# RA register map
Vendor: Renesas; Series: All Chips; File version: x.xx
Registers are 32-bit, read-write, reset 0x0 unless marked. A register's access mark holds for its fields unless they carry their own. Offsets are from the block's base; [hi:lo] are bit positions; {n}, {i} and the like mark numbered series; 'fields as' and 'values as' point back to an identical list; <NAME> marks a mode.

## R_GPT0 — General PWM Timer
Base 0x40169000
Same registers: R_GPT10 0x40078A00, R_GPT11 0x40078B00, R_GPT12 0x40078C00, R_GPT13 0x40078D00, R_GPT{n} {0x40169000+0x100*n} (n=1..9)
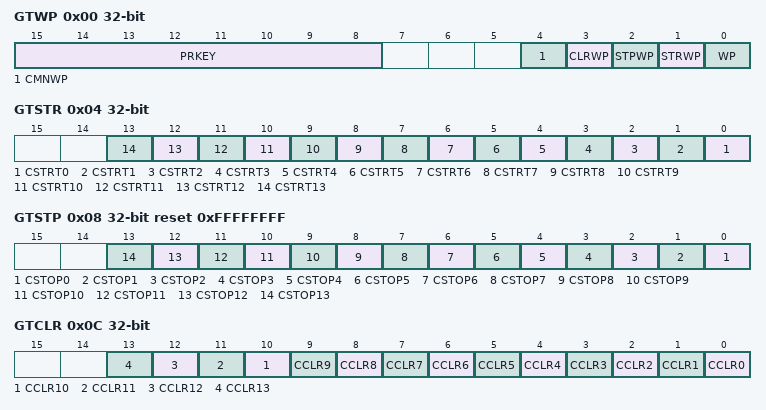
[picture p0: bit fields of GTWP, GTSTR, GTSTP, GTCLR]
0x00 GTWP — General PWM Timer Write-Protection Register
  [15:8] PRKEY wo — GTWP Key Code
    165=Written to these bits, the WP bits write is permitted; other=others (The WP bits write is not permitted.)
  [4] CMNWP — Common Register Write Disabled
    0=Write to the register is enabled; 1=Write to the register is disabled
  [3] CLRWP — GTCLR.CCLR Bit Write Disable
    0=Write to the bit is enabled; 1=Write to the bit is disabled
  [2] STPWP — GTSTP.CSTOP Bit Write Disable
    values as CLRWP
  [1] STRWP — GTSTR.CSTRT Bit Write Disable
    values as CLRWP
  [0] WP — Register Write Disable
    values as CMNWP
0x04 GTSTR — General PWM Timer Software Start Register
  [n] CSTRT{n} (n=0..13) — Channel GTCNT Count StartRead data shows each channel's counter status (GTCR.CST bit). 0 means counter stop. 1 means counter running.
    0=No effect (write) / counter stop (read); 1=GTCNT counter starts (write) / Counter running (read)
0x08 GTSTP reset 0xFFFFFFFF — General PWM Timer Software Stop Register
  [n] CSTOP{n} (n=0..13) — Channel GTCNT Count StopRead data shows each channel's counter status (GTCR.CST bit). 0 means counter runnning. 1 means counter stop.
    0=No effect (write) / counter running (read); 1=GPT GTCNT counter stops (write) / Counter stop (read)
0x0C GTCLR wo — General PWM Timer Software Clear Register
  [n] CCLR{n} (n=0..13) — Channel GTCNT Count Clear
    0=No effect; 1=GPT GTCNT counter clears
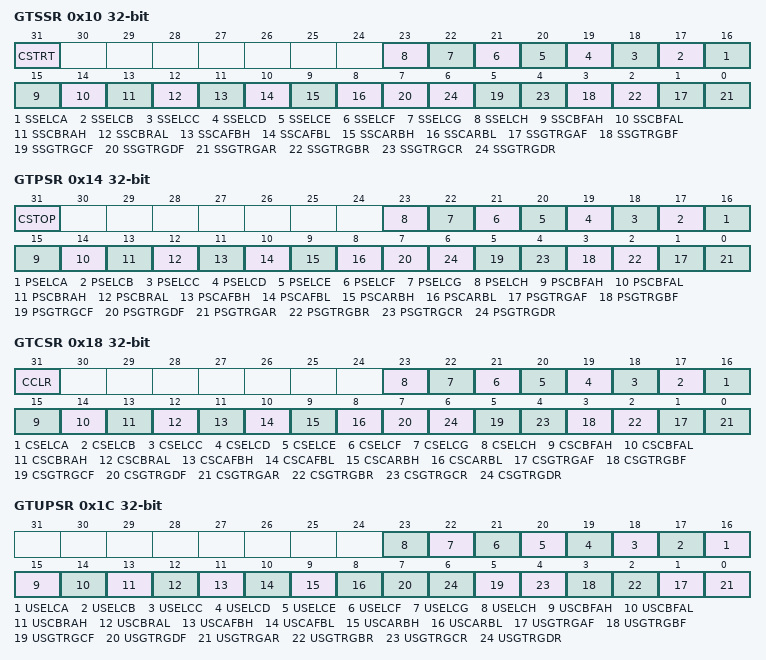
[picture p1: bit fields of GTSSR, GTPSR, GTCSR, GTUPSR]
0x10 GTSSR — General PWM Timer Start Source Select Register
  [31] CSTRT — Software Source Counter Start Enable
    0=Counter start is disable by the GTSTR register; 1=Counter start is enable by the GTSTR register
  [16] SSELC{x} (x=A,B,C,D,E,F,G,H; step 1) — ELC_GPT Event Source Counter Start Enable
    0=Counter start is disable at the ELC_GPT input; 1=Counter start is enable at the ELC_GPT input
  [15] SSCBFAH — GTIOCB Pin Falling Input during GTIOCA Value High Source Counter Start Enable
    0=Counter start is disable at the falling edge of GTIOCB input when GTIOCA input is 1; 1=Counter start is enable at the falling edge of GTIOCB input when GTIOCA input is 1
  [14] SSCBFAL — GTIOCB Pin Falling Input during GTIOCA Value Low Source Counter Start Enable
    0=Counter start is disable at the falling edge of GTIOCB input when GTIOCA input is 0; 1=Counter start is enable at the falling edge of GTIOCB input when GTIOCA input is 0
  [13] SSCBRAH — GTIOCB Pin Rising Input during GTIOCA Value High Source Counter Start Enable
    0=Counter start is disable at the rising edge of GTIOCB input when GTIOCA input is 1; 1=Counter start is enable at the rising edge of GTIOCB input when GTIOCA input is 1
  [12] SSCBRAL — GTIOCB Pin Rising Input during GTIOCA Value Low Source Counter Start Enable
    0=Counter start is disable at the rising edge of GTIOCB input when GTIOCA input is 0; 1=Counter start is enable at the rising edge of GTIOCB input when GTIOCA input is 0
  [11] SSCAFBH — GTIOCA Pin Falling Input during GTIOCB Value High Source Counter Start Enable
    0=Counter start is disable at the falling edge of GTIOCA input when GTIOCB input is 1; 1=Counter start is enable at the falling edge of GTIOCA input when GTIOCB input is 1
  [10] SSCAFBL — GTIOCA Pin Falling Input during GTIOCB Value Low Source Counter Start Enable
    0=Counter start is disable at the falling edge of GTIOCA input when GTIOCB input is 0; 1=Counter start is enable at the falling edge of GTIOCA input when GTIOCB input is 0
  [9] SSCARBH — GTIOCA Pin Rising Input during GTIOCB Value High Source Counter Start Enable
    0=Counter start is disable at the rising edge of GTIOCA input when GTIOCB input is 1; 1=Counter start is enable at the rising edge of GTIOCA input when GTIOCB input is 1
  [8] SSCARBL — GTIOCA Pin Rising Input during GTIOCB Value Low Source Counter Start Enable
    0=Counter start is disable at the rising edge of GTIOCA input when GTIOCB input is 0; 1=Counter start is enable at the rising edge of GTIOCA input when GTIOCB input is 0
  [1] SSGTRG{x}F (x=A,B,C,D; step 2) — GTETRG Pin Falling Input Source Counter Start Enable
    0=Counter start is disable at the falling edge of GTETRG input; 1=Counter start is enable at the falling edge of GTETRG input
  [0] SSGTRG{x}R (x=A,B,C,D; step 2) — GTETRG Pin Rising Input Source Counter Start Enable
    0=Counter start is disable at the rising edge of GTETRG input; 1=Counter start is enable at the rising edge of GTETRG input
0x14 GTPSR — General PWM Timer Stop Source Select Register
  [31] CSTOP — Software Source Counter Stop Enable
    0=Counter stop is disable by the GTSTP register; 1=Counter stop is enable by the GTSTP register
  [16] PSELC{x} (x=A,B,C,D,E,F,G,H; step 1) — ELC_GPTA Event Source Counter Stop Enable
    0=Counter stop is disable at the ELC_GPTA input; 1=Counter stop is enable at the ELC_GPTA input
  [15] PSCBFAH — GTIOCB Pin Falling Input during GTIOCA Value High Source Counter Stop Enable
    0=Counter stop is disable at the falling edge of GTIOCB input when GTIOCA input is 1; 1=Counter stop is enable at the falling edge of GTIOCB input when GTIOCA input is 1
  [14] PSCBFAL — GTIOCB Pin Falling Input during GTIOCA Value Low Source Counter Stop Enable
    0=Counter stop is disable at the falling edge of GTIOCB input when GTIOCA input is 0; 1=Counter stop is enable at the falling edge of GTIOCB input when GTIOCA input is 0
  [13] PSCBRAH — GTIOCB Pin Rising Input during GTIOCA Value High Source Counter Stop Enable
    0=Counter stop is disable at the rising edge of GTIOCB input when GTIOCA input is 1; 1=Counter stop is enable at the rising edge of GTIOCB input when GTIOCA input is 1
  [12] PSCBRAL — GTIOCB Pin Rising Input during GTIOCA Value Low Source Counter Stop Enable
    0=Counter stop is disable at the rising edge of GTIOCB input when GTIOCA input is 0; 1=Counter stop is enable at the rising edge of GTIOCB input when GTIOCA input is 0
  [11] PSCAFBH — GTIOCA Pin Falling Input during GTIOCB Value High Source Counter Stop Enable
    0=Counter stop is disable at the falling edge of GTIOCA input when GTIOCB input is 1; 1=Counter stop is enable at the falling edge of GTIOCA input when GTIOCB input is 1
  [10] PSCAFBL — GTIOCA Pin Falling Input during GTIOCB Value Low Source Counter Stop Enable
    0=Counter stop is disable at the falling edge of GTIOCA input when GTIOCB input is 0; 1=Counter stop is enable at the falling edge of GTIOCA input when GTIOCB input is 0
  [9] PSCARBH — GTIOCA Pin Rising Input during GTIOCB Value High Source Counter Stop Enable
    0=Counter stop is disable at the rising edge of GTIOCA input when GTIOCB input is 1; 1=Counter stop is enable at the rising edge of GTIOCA input when GTIOCB input is 1
  [8] PSCARBL — GTIOCA Pin Rising Input during GTIOCB Value Low Source Counter Stop Enable
    0=Counter stop is disable at the rising edge of GTIOCA input when GTIOCB input is 0; 1=Counter stop is enable at the rising edge of GTIOCA input when GTIOCB input is 0
  [1] PSGTRG{x}F (x=A,B,C,D; step 2) — GTETRG Pin Falling Input Source Counter Stop Enable
    0=Counter stop is disable at the falling edge of GTETRG input; 1=Counter stop is enable at the falling edge of GTETRG input
  [0] PSGTRG{x}R (x=A,B,C,D; step 2) — GTETRG Pin Rising Input Source Counter Stop Enable
    0=Counter stop is disable at the rising edge of GTETRG input; 1=Counter stop is enable at the rising edge of GTETRG input
0x18 GTCSR — General PWM Timer Clear Source Select Register
  [31] CCLR — Software Source Counter Clear Enable
    0=Counter clear is disable by the GTCLR register; 1=Counter clear is enable by the GTCLR register
  [16] CSELC{x} (x=A,B,C,D,E,F,G,H; step 1) — ELC_GPTA Event Source Counter Clear Enable
    0=Counter clear is disable at the ELC_GPTA input; 1=Counter clear is enable at the ELC_GPTA input
  [15] CSCBFAH — GTIOCB Pin Falling Input during GTIOCA Value High Source Counter Clear Enable
    0=Counter clear is disable at the falling edge of GTIOCB input when GTIOCA input is 1; 1=Counter clear is enable at the falling edge of GTIOCB input when GTIOCA input is 1
  [14] CSCBFAL — GTIOCB Pin Falling Input during GTIOCA Value Low Source Counter Clear Enable
    0=Counter clear is disable at the falling edge of GTIOCB input when GTIOCA input is 0; 1=Counter clear is enable at the falling edge of GTIOCB input when GTIOCA input is 0
  [13] CSCBRAH — GTIOCB Pin Rising Input during GTIOCA Value High Source Counter Clear Enable
    0=Counter clear is disable at the rising edge of GTIOCB input when GTIOCA input is 1; 1=Counter clear is enable at the rising edge of GTIOCB input when GTIOCA input is 1
  [12] CSCBRAL — GTIOCB Pin Rising Input during GTIOCA Value Low Source Counter Clear Enable
    0=Counter clear is disable at the rising edge of GTIOCB input when GTIOCA input is 0; 1=Counter clear is enable at the rising edge of GTIOCB input when GTIOCA input is 0
  [11] CSCAFBH — GTIOCA Pin Falling Input during GTIOCB Value High Source Counter Clear Enable
    0=Counter clear is disable at the falling edge of GTIOCA input when GTIOCB input is 1; 1=Counter clear is enable at the falling edge of GTIOCA input when GTIOCB input is 1
  [10] CSCAFBL — GTIOCA Pin Falling Input during GTIOCB Value Low Source Counter Clear Enable
    0=Counter clear is disable at the falling edge of GTIOCA input when GTIOCB input is 0; 1=Counter clear is enable at the falling edge of GTIOCA input when GTIOCB input is 0
  [9] CSCARBH — GTIOCA Pin Rising Input during GTIOCB Value High Source Counter Clear Enable
    0=Counter clear is disable at the rising edge of GTIOCA input when GTIOCB input is 1; 1=Counter clear is enable at the rising edge of GTIOCA input when GTIOCB input is 1
  [8] CSCARBL — GTIOCA Pin Rising Input during GTIOCB Value Low Source Counter Clear Enable
    0=Counter clear is disable at the rising edge of GTIOCA input when GTIOCB input is 0; 1=Counter clear is enable at the rising edge of GTIOCA input when GTIOCB input is 0
  [1] CSGTRG{x}F (x=A,B,C,D; step 2) — GTETRG Pin Falling Input Source Counter Clear Enable
    0=Counter clear is disable at the falling edge of GTETRG input; 1=Counter clear is enable at the falling edge of GTETRG input
  [0] CSGTRG{x}R (x=A,B,C,D; step 2) — GTETRG Pin Rising Input Source Counter Clear Enable
    0=Counter clear is disable at the rising edge of GTETRG input; 1=Counter clear is enable at the rising edge of GTETRG input
0x1C GTUPSR — General PWM Timer Up Count Source Select Register
  [16] USELC{x} (x=A,B,C,D,E,F,G,H; step 1) — ELC_GPT Event Source Counter Count Up Enable
    0=Counter count up is disable at the ELC_GPT input; 1=Counter count up is enable at the ELC_GPT input
  [15] USCBFAH — GTIOCB Pin Falling Input during GTIOCA Value High Source Counter Count Up Enable
    0=Counter count up is disable at the falling edge of GTIOCB input when GTIOCA input is 1; 1=Counter count up is enable at the falling edge of GTIOCB input when GTIOCA input is 1
  [14] USCBFAL — GTIOCB Pin Falling Input during GTIOCA Value Low Source Counter Count Up Enable
    0=Counter count up is disable at the falling edge of GTIOCB input when GTIOCA input is 0; 1=Counter count up is enable at the falling edge of GTIOCB input when GTIOCA input is 0
  [13] USCBRAH — GTIOCB Pin Rising Input during GTIOCA Value High Source Counter Count Up Enable
    0=Counter count up is disable at the rising edge of GTIOCB input when GTIOCA input is 1; 1=Counter count up is enable at the rising edge of GTIOCB input when GTIOCA input is 1
  [12] USCBRAL — GTIOCB Pin Rising Input during GTIOCA Value Low Source Counter Count Up Enable
    0=Counter count up is disable at the rising edge of GTIOCB input when GTIOCA input is 0; 1=Counter count up is enable at the rising edge of GTIOCB input when GTIOCA input is 0
  [11] USCAFBH — GTIOCA Pin Falling Input during GTIOCB Value High Source Counter Count Up Enable
    0=Counter count up is disable at the falling edge of GTIOCA input when GTIOCB input is 1; 1=Counter count up is enable at the falling edge of GTIOCA input when GTIOCB input is 1
  [10] USCAFBL — GTIOCA Pin Falling Input during GTIOCB Value Low Source Counter Count Up Enable
    0=Counter count up is disable at the falling edge of GTIOCA input when GTIOCB input is 0; 1=Counter count up is enable at the falling edge of GTIOCA input when GTIOCB input is 0
  [9] USCARBH — GTIOCA Pin Rising Input during GTIOCB Value High Source Counter Count Up Enable
    0=Counter count up is disable at the rising edge of GTIOCA input when GTIOCB input is 1; 1=Counter count up is enable at the rising edge of GTIOCA input when GTIOCB input is 1
  [8] USCARBL — GTIOCA Pin Rising Input during GTIOCB Value Low Source Counter Count Up Enable
    0=Counter count up is disable at the rising edge of GTIOCA input when GTIOCB input is 0; 1=Counter count up is enable at the rising edge of GTIOCA input when GTIOCB input is 0
  [1] USGTRG{x}F (x=A,B,C,D; step 2) — GTETRG Pin Falling Input Source Counter Count Up Enable
    0=Counter count up is disable at the falling edge of GTETRG input; 1=Counter count up is enable at the falling edge of GTETRG input
  [0] USGTRG{x}R (x=A,B,C,D; step 2) — GTETRG Pin Rising Input Source Counter Count Up Enable
    0=Counter count up is disable at the rising edge of GTETRG input; 1=Counter count up is enable at the rising edge of GTETRG input
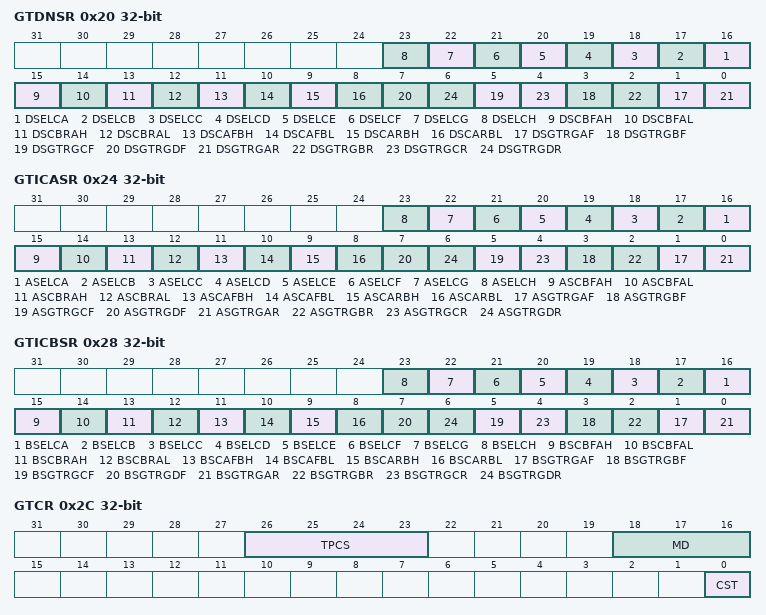
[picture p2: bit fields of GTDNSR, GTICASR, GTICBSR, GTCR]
0x20 GTDNSR — General PWM Timer Down Count Source Select Register
  [16] DSELC{x} (x=A,B,C,D,E,F,G,H; step 1) — ELC_GPT Event Source Counter Count Down Enable
    0=Counter count down is disable at the ELC_GPT input; 1=Counter count down is enable at the ELC_GPT input
  [15] DSCBFAH — GTIOCB Pin Falling Input during GTIOCA Value High Source Counter Count Down Enable
    0=Counter count down is disable at the falling edge of GTIOCB input when GTIOCA input is 1; 1=Counter count down is enable at the falling edge of GTIOCB input when GTIOCA input is 1
  [14] DSCBFAL — GTIOCB Pin Falling Input during GTIOCA Value Low Source Counter Count Down Enable
    0=Counter count down is disable at the falling edge of GTIOCB input when GTIOCA input is 0; 1=Counter count down is enable at the falling edge of GTIOCB input when GTIOCA input is 0
  [13] DSCBRAH — GTIOCB Pin Rising Input during GTIOCA Value High Source Counter Count Down Enable
    0=Counter count down is disable at the rising edge of GTIOCB input when GTIOCA input is 1; 1=Counter count down is enable at the rising edge of GTIOCB input when GTIOCA input is 1
  [12] DSCBRAL — GTIOCB Pin Rising Input during GTIOCA Value Low Source Counter Count Down Enable
    0=Counter count down is disable at the rising edge of GTIOCB input when GTIOCA input is 0; 1=Counter count down is enable at the rising edge of GTIOCB input when GTIOCA input is 0
  [11] DSCAFBH — GTIOCA Pin Falling Input during GTIOCB Value High Source Counter Count Down Enable
    0=Counter count down is disable at the falling edge of GTIOCA input when GTIOCB input is 1; 1=Counter count down is enable at the falling edge of GTIOCA input when GTIOCB input is 1
  [10] DSCAFBL — GTIOCA Pin Falling Input during GTIOCB Value Low Source Counter Count Down Enable
    0=Counter count down is disable at the falling edge of GTIOCA input when GTIOCB input is 0; 1=Counter count down is enable at the falling edge of GTIOCA input when GTIOCB input is 0
  [9] DSCARBH — GTIOCA Pin Rising Input during GTIOCB Value High Source Counter Count Down Enable
    0=Counter count down is disable at the rising edge of GTIOCA input when GTIOCB input is 1; 1=Counter count down is enable at the rising edge of GTIOCA input when GTIOCB input is 1
  [8] DSCARBL — GTIOCA Pin Rising Input during GTIOCB Value Low Source Counter Count Down Enable
    0=Counter count down is disable at the rising edge of GTIOCA input when GTIOCB input is 0; 1=Counter count down is enable at the rising edge of GTIOCA input when GTIOCB input is 0
  [1] DSGTRG{x}F (x=A,B,C,D; step 2) — GTETRG Pin Falling Input Source Counter Count Down Enable
    0=Counter count down is disable at the falling edge of GTETRG input; 1=Counter count down is enable at the falling edge of GTETRG input
  [0] DSGTRG{x}R (x=A,B,C,D; step 2) — GTETRG Pin Rising Input Source Counter Count Down Enable
    0=Counter count down is disable at the rising edge of GTETRG input; 1=Counter count down is enable at the rising edge of GTETRG input
0x24 GTICASR — General PWM Timer Input Capture Source Select Register A
  [16] ASELC{x} (x=A,B,C,D,E,F,G,H; step 1) — ELC_GPT Event Source GTCCRA Input Capture Enable
    0=GTCCRA input capture is disable at the ELC_GPT input; 1=GTCCRA input capture is enable at the ELC_GPT input
  [15] ASCBFAH — GTIOCB Pin Falling Input during GTIOCA Value High Source GTCCRA Input Capture Enable
    0=GTCCRA input capture is disable at the falling edge of GTIOCB input when GTIOCA input is 1; 1=GTCCRA input capture is enable at the falling edge of GTIOCB input when GTIOCA input is 1
  [14] ASCBFAL — GTIOCB Pin Falling Input during GTIOCA Value Low Source GTCCRA Input Capture Enable
    0=GTCCRA input capture is disable at the falling edge of GTIOCB input when GTIOCA input is 0; 1=GTCCRA input capture is enable at the falling edge of GTIOCB input when GTIOCA input is 0
  [13] ASCBRAH — GTIOCB Pin Rising Input during GTIOCA Value High Source GTCCRA Input Capture Enable
    0=GTCCRA input capture is disable at the rising edge of GTIOCB input when GTIOCA input is 1; 1=GTCCRA input capture is enable at the rising edge of GTIOCB input when GTIOCA input is 1
  [12] ASCBRAL — GTIOCB Pin Rising Input during GTIOCA Value Low Source GTCCRA Input Capture Enable
    0=GTCCRA input capture is disable at the rising edge of GTIOCB input when GTIOCA input is 0; 1=GTCCRA input capture is enable at the rising edge of GTIOCB input when GTIOCA input is 0
  [11] ASCAFBH — GTIOCA Pin Falling Input during GTIOCB Value High Source GTCCRA Input Capture Enable
    0=GTCCRA input capture is disable at the falling edge of GTIOCA input when GTIOCB input is 1; 1=GTCCRA input capture is enable at the falling edge of GTIOCA input when GTIOCB input is 1
  [10] ASCAFBL — GTIOCA Pin Falling Input during GTIOCB Value Low Source GTCCRA Input Capture Enable
    0=GTCCRA input capture is disable at the falling edge of GTIOCA input when GTIOCB input is 0; 1=GTCCRA input capture is enable at the falling edge of GTIOCA input when GTIOCB input is 0
  [9] ASCARBH — GTIOCA Pin Rising Input during GTIOCB Value High Source GTCCRA Input Capture Enable
    0=GTCCRA input capture is disable at the rising edge of GTIOCA input when GTIOCB input is 1; 1=GTCCRA input capture is enable at the rising edge of GTIOCA input when GTIOCB input is 1
  [8] ASCARBL — GTIOCA Pin Rising Input during GTIOCB Value Low Source GTCCRA Input Capture Enable
    0=GTCCRA input capture is disable at the rising edge of GTIOCA input when GTIOCB input is 0; 1=GTCCRA input capture is enable at the rising edge of GTIOCA input when GTIOCB input is 0
  [1] ASGTRG{x}F (x=A,B,C,D; step 2) — GTETRG Pin Falling Input Source GTCCRA Input Capture Enable
    0=GTCCRA input capture is disable at the falling edge of GTETRG input; 1=GTCCRA input capture is enable at the falling edge of GTETRG input
  [0] ASGTRG{x}R (x=A,B,C,D; step 2) — GTETRG Pin Rising Input Source GTCCRA Input Capture Enable
    0=GTCCRA input capture is disable at the rising edge of GTETRG input; 1=GTCCRA input capture is enable at the rising edge of GTETRG input
0x28 GTICBSR — General PWM Timer Input Capture Source Select Register B
  [16] BSELC{x} (x=A,B,C,D,E,F,G,H; step 1) — ELC_GPT Event Source GTCCRB Input Capture Enable
    0=GTCCRB input capture is disable at the ELC_GPT input; 1=GTCCRB input capture is enable at the ELC_GPT input
  [15] BSCBFAH — GTIOCB Pin Falling Input during GTIOCA Value High Source GTCCRB Input Capture Enable
    0=GTCCRB input capture is disable at the falling edge of GTIOCB input when GTIOCA input is 1; 1=GTCCRB input capture is enable at the falling edge of GTIOCB input when GTIOCA input is 1
  [14] BSCBFAL — GTIOCB Pin Falling Input during GTIOCA Value Low Source GTCCRB Input Capture Enable
    0=GTCCRB input capture is disable at the falling edge of GTIOCB input when GTIOCA input is 0; 1=GTCCRB input capture is enable at the falling edge of GTIOCB input when GTIOCA input is 0
  [13] BSCBRAH — GTIOCB Pin Rising Input during GTIOCA Value High Source GTCCRB Input Capture Enable
    0=GTCCRB input capture is disable at the rising edge of GTIOCB input when GTIOCA input is 1; 1=GTCCRB input capture is enable at the rising edge of GTIOCB input when GTIOCA input is 1
  [12] BSCBRAL — GTIOCB Pin Rising Input during GTIOCA Value Low Source GTCCRB Input Capture Enable
    0=GTCCRB input capture is disable at the rising edge of GTIOCB input when GTIOCA input is 0; 1=GTCCRB input capture is enable at the rising edge of GTIOCB input when GTIOCA input is 0
  [11] BSCAFBH — GTIOCA Pin Falling Input during GTIOCB Value High Source GTCCRB Input Capture Enable
    0=GTCCRB input capture is disable at the falling edge of GTIOCA input when GTIOCB input is 1; 1=GTCCRB input capture is enable at the falling edge of GTIOCA input when GTIOCB input is 1
  [10] BSCAFBL — GTIOCA Pin Falling Input during GTIOCB Value Low Source GTCCRB Input Capture Enable
    0=GTCCRB input capture is disable at the falling edge of GTIOCA input when GTIOCB input is 0; 1=GTCCRB input capture is enable at the falling edge of GTIOCA input when GTIOCB input is 0
  [9] BSCARBH — GTIOCA Pin Rising Input during GTIOCB Value High Source GTCCRB Input Capture Enable
    0=GTCCRB input capture is disable at the rising edge of GTIOCA input when GTIOCB input is 1; 1=GTCCRB input capture is enable at the rising edge of GTIOCA input when GTIOCB input is 1
  [8] BSCARBL — GTIOCA Pin Rising Input during GTIOCB Value Low Source GTCCRB Input Capture Enable
    0=GTCCRB input capture is disable at the rising edge of GTIOCA input when GTIOCB input is 0; 1=GTCCRB input capture is enable at the rising edge of GTIOCA input when GTIOCB input is 0
  [1] BSGTRG{x}F (x=A,B,C,D; step 2) — GTETRG Pin Falling Input Source GTCCRB Input Capture Enable
    0=GTCCRB input capture is disable at the falling edge of GTETRG input; 1=GTCCRB input capture is enable at the falling edge of GTETRG input
  [0] BSGTRG{x}R (x=A,B,C,D; step 2) — GTETRG Pin Rising Input Source GTCCRB Input Capture Enable
    0=GTCCRB input capture is disable at the rising edge of GTETRG input; 1=GTCCRB input capture is enable at the rising edge of GTETRG input
0x2C GTCR — General PWM Timer Control Register
  [26:23] TPCS — Timer Prescaler Select
    0=PCLK/1; 1=PCLK/2; 2=PCLK/4; 3=PCLK/8; 4=PCLK/16; 5=PCLK/32; 6=PCLK/64; 8=PCLK/256; 10=PCLK/1024; 12=GTETRGA; 13=GTETRGB; 14=GTETRGC; 15=GTETRGD; other=others (Setting prohibied)
  [18:16] MD — Mode Select
    0=Saw-wave PWM mode (single buffer or double buffer possible); 1=Saw-wave one-shot pulse mode (fixed buffer operation); 2=Setting prohibited; 3=Setting prohibited; 4=Triangle-wave PWM mode 1 (16-bit transfer at crest) (single buffer or double buffer possible); 5=Triangle-wave PWM mode 2 (16-bit transfer at crest and trough) (single buffer or double buffer possible); 6=Triangle-wave PWM mode 3 (32-bit transfer at trough) fixed buffer operation); 7=Setting prohibited
  [0] CST — Count Start
    0=Count operation is stopped; 1=Count operation is performed
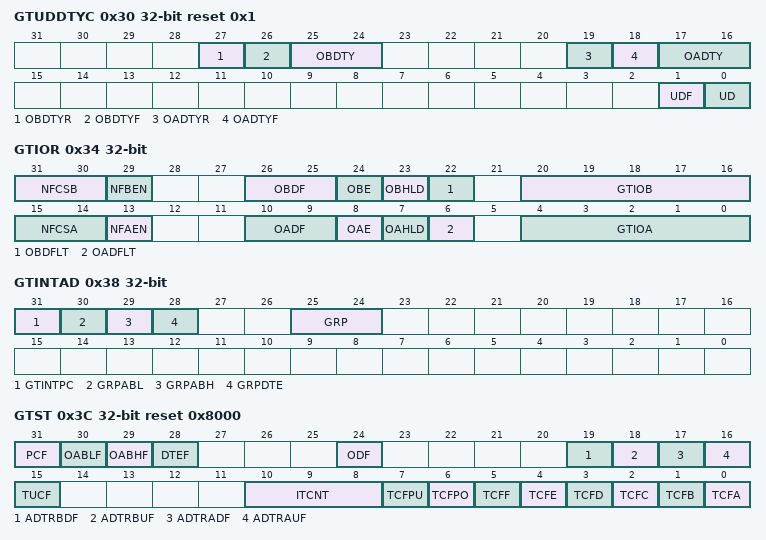
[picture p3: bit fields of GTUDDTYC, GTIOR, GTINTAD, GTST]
0x30 GTUDDTYC reset 0x1 — General PWM Timer Count Direction and Duty Setting Register
  [27] OBDTYR — GTIOCB Output Value Selecting after Releasing 0 percent/100 percent Duty Setting
    0=Apply output value set in 0 percent/100 percent duty to GTIOB[3:2] function after releasing 0 percent/100 percent duty setting; 1=Apply masked compare match output value to GTIOB[3:2] function after releasing 0 percent/100 percent duty setting
  [26] OBDTYF — Forcible GTIOCB Output Duty Setting
    0=Not forcibly set; 1=Forcibly set
  [25:24] OBDTY — GTIOCB Output Duty Setting
    0=GTIOCB pin duty is depend on compare match; 1=GTIOCB pin duty is depend on compare match; 2=GTIOCB pin duty 0 percent; 3=GTIOCB pin duty 100 percent
  [19] OADTYR — GTIOCA Output Value Selecting after Releasing 0 percent/100 percent Duty Setting
    0=Apply output value set in 0 percent/100 percent duty to GTIOA[3:2] function after releasing 0 percent/100 percent duty setting; 1=Apply masked compare match output value to GTIOA[3:2] function after releasing 0 percent/100 percent duty setting
  [18] OADTYF — Forcible GTIOCA Output Duty Setting
    0=Not forcibly set; 1=Forcibly set
  [17:16] OADTY — GTIOCA Output Duty Setting
    0=GTIOCA pin duty is depend on compare match; 1=GTIOCA pin duty is depend on compare match; 2=GTIOCA pin duty 0 percent; 3=GTIOCA pin duty 100 percent
  [1] UDF — Forcible Count Direction Setting
    0=Not forcibly set; 1=Forcibly set
  [0] UD — Count Direction Setting
    0=GTCNT counts down; 1=GTCNT counts up
0x34 GTIOR — General PWM Timer I/O Control Register
  [31:30] NFCSB — Noise Filter B Sampling Clock Select
    0=PCLK/1; 1=PCLK/4; 2=PCLK/16; 3=PCLK/64
  [29] NFBEN — Noise Filter B Enable
    0=The noise filter for the GTIOCB pin is disabled; 1=The noise filter for the GTIOCB pin is enabled
  [26:25] OBDF — GTIOCB Pin Disable Value Setting
    0=Output disable is prohibited; 1=GTIOCB pin is set to Hi-Z when output disable is performed; 2=GTIOCB pin is set to 0 when output disable is performed; 3=GTIOCB pin is set to 1 when output disable is performed
  [24] OBE — GTIOCB Pin Output Enable
    0=Output is disabled; 1=Output is enabled
  [23] OBHLD — GTIOCB Pin Output Setting at the Start/Stop Count
    0=The GTIOCB pin output level at start/stop of counting depends on the register setting; 1=The GTIOCB pin output level is retained at start/stop of counting
  [22] OBDFLT — GTIOCB Pin Output Value Setting at the Count Stop
    0=The GTIOCB pin outputs low when counting is stopped; 1=The GTIOCB pin outputs high when counting is stopped
  [20:16] GTIOB — GTIOCB Pin Function Select
    0=Initial output is Low. Output retained at cycle end. Output retained at GTCCRB compare match.; 1=Initial output is Low. Output retained at cycle end. Low output at GTCCRB compare match.; 2=Initial output is Low. Output retained at cycle end. High output at GTCCRB compare match.; 3=Initial output is Low. Output retained at cycle end. Output toggled at GTCCRB compare match.; 4=Initial output is Low. Low output at cycle end. Output retained at GTCCRB compare match.; 5=Initial output is Low. Low output at cycle end. Low output at GTCCRB compare match.; 6=Initial output is Low. Low output at cycle end. High output at GTCCRB compare match.; 7=Initial output is Low. Low output at cycle end. Output toggled at GTCCRB compare match.; 8=Initial output is Low. High output at cycle end. Output retained at GTCCRB compare match.; 9=Initial output is Low. High output at cycle end. Low output at GTCCRB compare match.; 10=Initial output is Low. High output at cycle end. High output at GTCCRB compare match.; 11=Initial output is Low. High output at cycle end. Output toggled at GTCCRB compare match.; 12=Initial output is Low. Output toggled at cycle end. Output retained at GTCCRB compare match.; 13=Initial output is Low. Output toggled at cycle end. Low output at GTCCRB compare match.; 14=Initial output is Low. Output toggled at cycle end. High output at GTCCRB compare match.; 15=Initial output is Low. Output toggled at cycle end. Output toggled at GTCCRB compare match.; 16=Initial output is High. Output retained at cycle end. Output retained at GTCCRB compare match.; 17=Initial output is High. Output retained at cycle end. Low output at GTCCRB compare match.; 18=Initial output is High. Output retained at cycle end. High output at GTCCRB compare match.; 19=Initial output is High. Output retained at cycle end. Output toggled at GTCCRB compare match.; 20=Initial output is High. Low output at cycle end. Output retained at GTCCRB compare match.; 21=Initial output is High. Low output at cycle end. Low output at GTCCRB compare match.; 22=Initial output is High. Low output at cycle end. High output at GTCCRB compare match.; 23=Initial output is High. Low output at cycle end. Output toggled at GTCCRB compare match.; 24=Initial output is High. High output at cycle end. Output retained at GTCCRB compare match.; 25=Initial output is High. High output at cycle end. Low output at GTCCRB compare match.; 26=Initial output is High. High output at cycle end. High output at GTCCRB compare match.; 27=Initial output is High. High output at cycle end. Output toggled at GTCCRB compare match.; 28=Initial output is High. Output toggled at cycle end. Output retained at GTCCRB compare match.; 29=Initial output is High. Output toggled at cycle end. Low output at GTCCRB compare match.; 30=Initial output is High. Output toggled at cycle end. High output at GTCCRB compare match.; 31=Initial output is High. Output toggled at cycle end. Output toggled at GTCCRB compare match.
  [15:14] NFCSA — Noise Filter A Sampling Clock Select
    0=PCLK/1; 1=PCLK/4; 2=PCLK/16; 3=PCLK/64
  [13] NFAEN — Noise Filter A Enable
    0=The noise filter for the GTIOCA pin is disabled; 1=The noise filter for the GTIOCA pin is enabled
  [10:9] OADF — GTIOCA Pin Disable Value Setting
    0=Output disable is prohibited; 1=GTIOCA pin is set to Hi-Z when output disable is performed; 2=GTIOCA pin is set to 0 when output disable is performed; 3=GTIOCA pin is set to 1 when output disable is performed
  [8] OAE — GTIOCA Pin Output Enable
    0=Output is disabled; 1=Output is enabled
  [7] OAHLD — GTIOCA Pin Output Setting at the Start/Stop Count
    0=The GTIOCA pin output level at start/stop of counting depends on the register setting; 1=The GTIOCA pin output level is retained at start/stop of counting
  [6] OADFLT — GTIOCA Pin Output Value Setting at the Count Stop
    0=The GTIOCA pin outputs low when counting is stopped; 1=The GTIOCA pin outputs high when counting is stopped
  [4:0] GTIOA — GTIOCA Pin Function Select
    0=Initial output is Low. Output retained at cycle end. Output retained at GTCCRA compare match.; 1=Initial output is Low. Output retained at cycle end. Low output at GTCCRA compare match.; 2=Initial output is Low. Output retained at cycle end. High output at GTCCRA compare match.; 3=Initial output is Low. Output retained at cycle end. Output toggled at GTCCRA compare match.; 4=Initial output is Low. Low output at cycle end. Output retained at GTCCRA compare match.; 5=Initial output is Low. Low output at cycle end. Low output at GTCCRA compare match.; 6=Initial output is Low. Low output at cycle end. High output at GTCCRA compare match.; 7=Initial output is Low. Low output at cycle end. Output toggled at GTCCRA compare match.; 8=Initial output is Low. High output at cycle end. Output retained at GTCCRA compare match.; 9=Initial output is Low. High output at cycle end. Low output at GTCCRA compare match.; 10=Initial output is Low. High output at cycle end. High output at GTCCRA compare match.; 11=Initial output is Low. High output at cycle end. Output toggled at GTCCRA compare match.; 12=Initial output is Low. Output toggled at cycle end. Output retained at GTCCRA compare match.; 13=Initial output is Low. Output toggled at cycle end. Low output at GTCCRA compare match.; 14=Initial output is Low. Output toggled at cycle end. High output at GTCCRA compare match.; 15=Initial output is Low. Output toggled at cycle end. Output toggled at GTCCRA compare match.; 16=Initial output is High. Output retained at cycle end. Output retained at GTCCRA compare match.; 17=Initial output is High. Output retained at cycle end. Low output at GTCCRA compare match.; 18=Initial output is High. Output retained at cycle end. High output at GTCCRA compare match.; 19=Initial output is High. Output retained at cycle end. Output toggled at GTCCRA compare match.; 20=Initial output is High. Low output at cycle end. Output retained at GTCCRA compare match.; 21=Initial output is High. Low output at cycle end. Low output at GTCCRA compare match.; 22=Initial output is High. Low output at cycle end. High output at GTCCRA compare match.; 23=Initial output is High. Low output at cycle end. Output toggled at GTCCRA compare match.; 24=Initial output is High. High output at cycle end. Output retained at GTCCRA compare match.; 25=Initial output is High. High output at cycle end. Low output at GTCCRA compare match.; 26=Initial output is High. High output at cycle end. High output at GTCCRA compare match.; 27=Initial output is High. High output at cycle end. Output toggled at GTCCRA compare match.; 28=Initial output is High. Output toggled at cycle end. Output retained at GTCCRA compare match.; 29=Initial output is High. Output toggled at cycle end. Low output at GTCCRA compare match.; 30=Initial output is High. Output toggled at cycle end. High output at GTCCRA compare match.; 31=Initial output is High. Output toggled at cycle end. Output toggled at GTCCRA compare match.
0x38 GTINTAD — General PWM Timer Interrupt Output Setting Register
  [31] GTINTPC — Period Count Function Finish Interrupt Enable
    0=Interrupt request is disabled; 1=Interrupt request is enabled
  [30] GRPABL — Same Time Output Level Low Disable Request Enable
    0=Same time output level low disable request is disabled; 1=Same time output level low disable request is enabled
  [29] GRPABH — Same Time Output Level High Disable Request Enable
    0=Same time output level high disable request is disabled; 1=Same time output level high disable request is enabled
  [28] GRPDTE — Dead Time Error Output Disable Request Enable
    0=Disable dead time error output disable request; 1=Enable dead time error output disable request
  [25:24] GRP — Output Disable Source Select
    0=Group A output disable request; 1=Group B output disable request; 2=Group C output disable request; 3=Group D output disable request; other=others (Setting prohibited)
0x3C GTST reset 0x8000 — General PWM Timer Status Register
  [31] PCF — Period Count Function Finish Flag
    0=No period count function finish has occurred; 1=A period count function finish has occurred
  [30] OABLF ro — Same Time Output Level Low Disable Request Enable
    0=GTIOCA pin and GTIOCB pin don't output 0 at the same time; 1=GTIOCA pin and GTIOCB pin output 0 at the same time
  [29] OABHF ro — Same Time Output Level High Disable Request Enable
    0=GTIOCA pin and GTIOCB pin don't output 1 at the same time; 1=GTIOCA pin and GTIOCB pin output 1 at the same time
  [28] DTEF ro — Dead Time Error Flag
    0=No dead time error has occurred; 1=A dead time error has occurred
  [24] ODF ro — Output Disable Flag
    0=No output disable request is generated; 1=An output disable request is generated
  [19] ADTRBDF — GTADTRB Compare Match(Down-Counting) A/D Convertor Start Request Flag
    0=No compare match of GTADTRB at down-counting is generated; 1=A compare match of GTADTRB at down-counting is generated
  [18] ADTRBUF — GTADTRB Compare Match(Up-Counting) A/D Convertor Start Request Flag
    0=No compare match of GTADTRB at up-counting is generated; 1=A compare match of GTADTRB at up-counting is generated
  [17] ADTRADF — GTADTRA Compare Match(Down-Counting) A/D Convertor Start Request Flag
    0=No compare match of GTADTRA at down-counting is generated; 1=A compare match of GTADTRA at down-counting is generated
  [16] ADTRAUF — GTADTRA Compare Match (Up-Counting) A/D Converter Start Request Interrupt Enable
    0=No compare match of GTADTRA at up-counting is generated; 1=A compare match of GTADTRA at up-counting is generated
  [15] TUCF ro — Count Direction Flag
    0=The GTCNT counter counts downward; 1=The GTCNT counter counts upward
  [10:8] ITCNT ro — GTCIV/GTCIU Interrupt Skipping Count Counter(Counter for counting the number of times a timer interrupt has been skipped.)
  [7] TCFPU — Underflow Flag
    0=No underflow (trough) has occurred; 1=An underflow (trough) has occurred
  [6] TCFPO — Overflow Flag
    0=No overflow (crest) has occurred; 1=An overflow (crest) has occurred
  [5] TCFF — Input Compare Match Flag F
    0=No compare match of GTCCRF is generated; 1=A compare match of GTCCRF is generated
  [4] TCFE — Input Compare Match Flag E
    0=No compare match of GTCCRE is generated; 1=A compare match of GTCCRE is generated
  [3] TCFD — Input Compare Match Flag D
    0=No compare match of GTCCRD is generated; 1=A compare match of GTCCRD is generated
  [2] TCFC — Input Compare Match Flag C
    0=No compare match of GTCCRC is generated; 1=A compare match of GTCCRC is generated
  [1] TCFB — Input Capture/Compare Match Flag B
    0=No input capture/compare match of GTCCRB is generated; 1=An input capture/compare match of GTCCRB is generated
  [0] TCFA — Input Capture/Compare Match Flag A
    0=No input capture/compare match of GTCCRA is generated; 1=An input capture/compare match of GTCCRA is generated
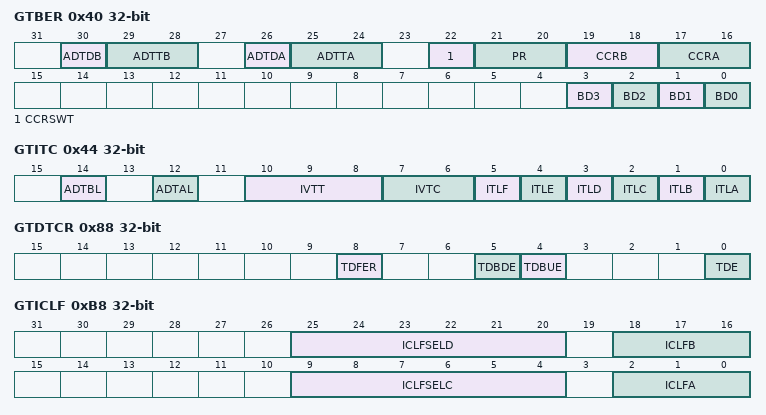
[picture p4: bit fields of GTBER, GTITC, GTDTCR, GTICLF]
0x40 GTBER — General PWM Timer Buffer Enable Register
  [30] ADTDB — GTADTRB Double Buffer Operation
    0=Single buffer operation (GTADTBRB --> GTADTRB); 1=Double buffer operation (GTADTDBRB --> GTADTBRB --> GTADTDRB)
  [29:28] ADTTB — GTADTRB Buffer Transfer Timing Select in the Triangle wavesNOTE: In the Saw waves, values other than 0 0: Transfer at an underflow (in down-counting) or overflow (in up-counting) is performed.
    0=No transfer; 1=Transfer at crest; 2=Transfer at trough; 3=Transfer at both crest and trough
  [26] ADTDA — GTADTRA Double Buffer Operation
    0=Single buffer operation (GTADTBRA --> GTADTRA); 1=Double buffer operation (GTADTDBRA --> GTADTBRA --> GTADTDRA)
  [25:24] ADTTA — GTADTRA Buffer Transfer Timing Select in the Triangle wavesNOTE: In the Saw waves, values other than 0 0: Transfer at an underflow (in down-counting) or overflow (in up-counting) is performed.
    values as ADTTB
  [22] CCRSWT wo — GTCCRA and GTCCRB Forcible Buffer OperationThis bit is read as 0.
    0=no effect; 1=Forcibly performs buffer transfer of GTCCRA and GTCCRB. This bit automatically returns to 0 after the writing of 1.
  [21:20] PR — GTPR Buffer Operation
    0=Buffer operation is not performed; 1=Single buffer operation (GTPBR --> GTPR); other=others (Setting prohibited)
  [19:18] CCRB — GTCCRB Buffer Operation
    0=Buffer operation is not performed; 1=Single buffer operation (GTCCRB <--> GTCCRE); 2=Double buffer operation (GTCCRB <--> GTCCRE <--> GTCCRF); 3=Double buffer operation (GTCCRB <--> GTCCRE <--> GTCCRF)
  [17:16] CCRA — GTCCRA Buffer Operation
    0=Buffer operation is not performed; 1=Single buffer operation (GTCCRA <--> GTCCRC); 2=Double buffer operation (GTCCRA <--> GTCCRC <--> GTCCRD); 3=Double buffer operation (GTCCRA <--> GTCCRC <--> GTCCRD)
  [3] BD3 — BD[3]: GTDV Buffer Operation DisableBD[2]
    0=Enable buffer operation; 1=Disable buffer operation
  [2] BD2 — BD[2]: GTADTR Buffer Operation DisableBD
    0=Enable buffer operation; 1=Disable buffer operation
  [1] BD1 — BD[1]: GTPR Buffer Operation Disable
    0=Buffer operation is enabled; 1=Buffer operation is disabled
  [0] BD0 — BD[0]: GTCCR Buffer Operation Disable
    values as BD1
0x44 GTITC — General PWM Timer Interrupt and A/D Converter Start Request Skipping Setting Register
  [14] ADTBL — GTADTRB A/D Converter Start Request Link
    0=Do not link with GPTn_OVF/GPTn_UDF interrupt skipping function; 1=Link with GPTn_OVF/GPTn_UDF interrupt skipping function
  [12] ADTAL — GTADTRA A/D Converter Start Request Link
    values as ADTBL
  [10:8] IVTT — GPT_OVF/GPT_UDF Interrupt Skipping Count Select
    0=No skipping; {v}=Skipping count of {v} (v=1..7)
  [7:6] IVTC — GPT_OVF/GPT_UDF Interrupt Skipping Function Select
    0=Do not perform skipping; 1=Count and skip both overflow and underflow for saw waves and crest for triangle waves; 2=Count and skip both overflow and underflow for saw waves and trough for triangle waves; 3=Count and skip both overflow and underflow for saw waves and both crest and trough for triangle waves
  [5] ITLF — GTCCRF Compare Match Interrupt Link
    values as ADTBL
  [4] ITLE — GTCCRE Compare Match Interrupt Link
    values as ADTBL
  [3] ITLD — GTCCRD Compare Match Interrupt Link
    values as ADTBL
  [2] ITLC — GTCCRC Compare Match Interrupt Link
    values as ADTBL
  [1] ITLB — GTCCRB Compare Match/Input Capture Interrupt Link
    values as ADTBL
  [0] ITLA — GTCCRA Compare Match/Input Capture Interrupt Link
    values as ADTBL
0x48 GTCNT — General PWM Timer Counter
  [31:0] GTCNT — Counter
{0x4C+4i} GTCCR[{i}] (i=0..5) reset 0xFFFFFFFF — General PWM Timer Compare Capture Register
  [31:0] GTCCR — Compare Capture Register A
0x64 GTPR reset 0xFFFFFFFF — General PWM Timer Cycle Setting Register
  [31:0] GTPR — Cycle Setting Register
0x68 GTPBR reset 0xFFFFFFFF — General PWM Timer Cycle Setting Buffer Register
  [31:0] GTPBR — Cycle Setting Buffer Register
0x6C GTPDBR reset 0xFFFFFFFF — General PWM Timer Cycle Setting Double-Buffer Register
  [31:0] GTPDBR — Cycle Setting Double-Buffer Register
0x70 GTADTRA reset 0xFFFFFFFF — A/D Converter Start Request Timing Register A
0x74 GTADTBRA reset 0xFFFFFFFF — A/D Converter Start Request Timing Buffer Register A
0x78 GTADTDBRA reset 0xFFFFFFFF — A/D Converter Start Request Timing Double-Buffer Register A
0x7C GTADTRB reset 0xFFFFFFFF — A/D Converter Start Request Timing Register B
0x80 GTADTBRB reset 0xFFFFFFFF — A/D Converter Start Request Timing Buffer Register B
0x84 GTADTDBRB reset 0xFFFFFFFF — A/D Converter Start Request Timing Double-Buffer Register B
0x88 GTDTCR — General PWM Timer Dead Time Control Register
  [8] TDFER — GTDVD Setting
    0=Set GTDVU and GTDVD separately; 1=Automatically set the value written to GTDVU to GTDVD
  [5] TDBDE — GTDVD Buffer Operation Enable
    0=Disable GTDVD buffer operation; 1=Enable GTDVD buffer operation
  [4] TDBUE — GTDVU Buffer Operation Enable
    0=Disable GTDVU buffer operation; 1=Enable GTDVU buffer operation
  [0] TDE — Negative-Phase Waveform Setting
    0=GTCCRB is set without using GTDVU and GTDVD; 1=GTDVU and GTDVD are used to set the compare match value for negative-phase waveform with dead time automatically in GTCCRB
0x8C GTDVU reset 0xFFFFFFFF — General PWM Timer Dead Time Value Register U
  [31:0] GTDVU — Dead Time Value Register U
0x90 GTDVD reset 0xFFFFFFFF — General PWM Timer Dead Time Value Register D
  [31:0] GTDVD — Dead Time Value Register D
0x94 GTDBU reset 0xFFFFFFFF — General PWM Timer Dead Time Buffer Register U
  [31:0] GTDVU — Dead Time Buffer Register U
0x98 GTDBD reset 0xFFFFFFFF — General PWM Timer Dead Time Buffer Register D
  [31:0] GTDBD — Dead Time Buffer Register D
0x9C GTSOS ro — General PWM Timer Output Protection Function Status Register
  [1:0] SOS — Output Protection Function Status
    0=Normal operation; 1=Protected state (GTCCRA = 0 is set during transfer at trough or crest); 2=Protected state (GTCCRA >= GTPR is set during transfer at trough); 3=Protected state (GTCCRA >= GTPR is set during transfer at crest)
0xA0 GTSOTR — General PWM Timer Output Protection Function Temporary Release Register
  [0] SOTR — Output Protection Function Temporary Release
    0=Do not release protected state; 1=Release protected state
0xB8 GTICLF — General PWM Timer Inter Channel Logical Operation Function Setting Register
  [25:20] ICLFSELD — Inter Channel Signal D Select
    0=GTIOC0A; 1=GTIOC0B; 2=GTIOC1A; 3=GTIOC1B; 4=GTIOC2A; 5=GTIOC2B; 6=GTIOC3A; 7=GTIOC3B; 8=GTIOC4A; 9=GTIOC4B; 10=GTIOC5A; 11=GTIOC5B; 12=GTIOC6A; 13=GTIOC6B; 14=GTIOC7A; 15=GTIOC7B; 16=GTIOC8A; 17=GTIOC8B; 18=GTIOC9A; 19=GTIOC9B; other=Others (Setting prohibited)
  [18:16] ICLFB — GTIOCnB Output Logical Operation Function Select
    0=B (no delay); 1=NOT B (no delay); 2=D (1PCLKGPT delay); 3=NOT D (1PCLKGPT delay); 4=B AND D (1PCLKGPT delay); 5=B OR D (1PCLKGPTn delay); 6=B EXOR D (1PCLKGPT delay); 7=B NOR D (1PCLKGPT delay)
  [9:4] ICLFSELC — Inter Channel Signal C Select
    values as ICLFSELD
  [2:0] ICLFA — GTIOCnA Output Logical Operation Function Select
    0=A (no delay); 1=NOT A (no delay); 2=C (1PCLKGPT delay); 3=NOT C (1PCLKGPT delay); 4=A AND C (1PCLKGPT delay); 5=A OR C (1PCLKGPT delay); 6=A EXOR C (1PCLKGPT delay); 7=A NOR C (1PCLKGPT delay)
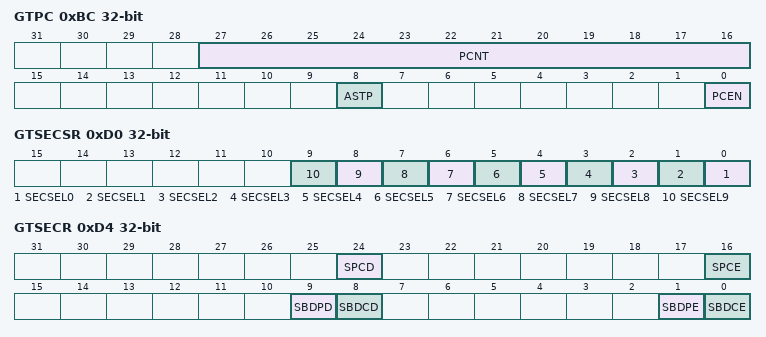
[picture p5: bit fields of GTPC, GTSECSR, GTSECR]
0xBC GTPC — General PWM Timer Period Count Register
  [27:16] PCNT — Period Counter
  [8] ASTP — Automatic Stop Function Enable
    0=Automatic stop function is disabled; 1=Automatic stop function is enabled
  [0] PCEN — Period Count Function Enable
    0=Period count function is disabled; 1=Period count function is enabled
0xD0 GTSECSR — General PWM Timer Operation Enable Bit Simultaneous Control Channel Select Register
  [all] fields
    0=Disable simultaneous control; 1=Enable simultaneous control
  [n] SECSEL{n} (n=0..9) — Channel {n} Operation Enable Bit Simultaneous Control Channel Select
0xD4 GTSECR — General PWM Timer Operation Enable Bit Simultaneous Control Register
  [24] SPCD — Period Count Function Simultaneous Disable
    0=Disable simultaneous disabling period count function; 1=Disable period count function simultaneously
  [16] SPCE — Period Count Function Simultaneous Enable
    0=Disable simultaneous enabling period count function; 1=Enable period count function simultaneously
  [9] SBDPD — GTPR Register Buffer Operation Simultaneous Disable
    0=Disable simultaneous disabling GTPR buffer operations; 1=Disable GTPR register buffer operations simultaneously
  [8] SBDCD — GTCCR Register Buffer Operation Simultaneous Disable
    0=Disable simultaneous disabling GTCCR buffer operations; 1=Disable GTCCR register buffer operations simultaneously
  [1] SBDPE — GTPR Register Buffer Operation Simultaneous Enable
    0=Disable simultaneous enabling GTPR buffer operations; 1=Enable GTPR register buffer operations simultaneously
  [0] SBDCE — GTCCR Register Buffer Operation Simultaneous Enable
    0=Disable simultaneous enabling GTCCR buffer operations; 1=Enable GTCCR register buffer operations simultaneously
